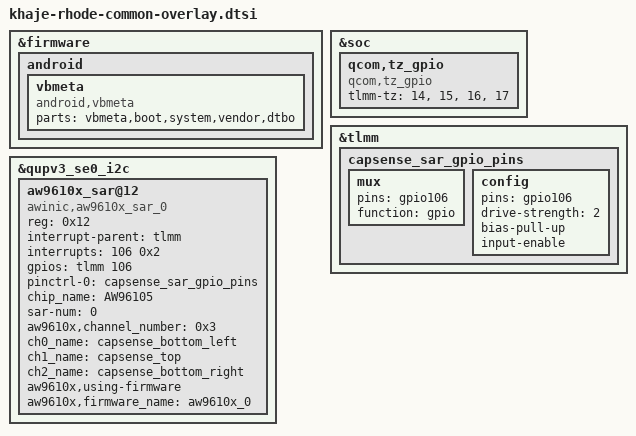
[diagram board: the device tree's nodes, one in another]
/* Copyright (c) 2019, The Linux Foundation. All rights reserved.
 *
 * This program is free software; you can redistribute it and/or modify
 * it under the terms of the GNU General Public License version 2 and
 * only version 2 as published by the Free Software Foundation.
 *
 * This program is distributed in the hope that it will be useful,
 * but WITHOUT ANY WARRANTY; without even the implied warranty of
 * MERCHANTABILITY or FITNESS FOR A PARTICULAR PURPOSE.  See the
 * GNU General Public License for more details.
 */

#include <dt-bindings/interrupt-controller/arm-gic.h>
#include "khaje-moto-common-overlay.dtsi"
#include "khaje-rhode-display.dtsi"
#include "khaje-rhode-fps-overlay_evb.dtsi"
#include "khaje-rhode-touchscreen-overlay.dtsi"

&firmware {
	android {
		vbmeta {
			compatible = "android,vbmeta";
			parts = "vbmeta,boot,system,vendor,dtbo";
		};
	};
};
&soc {
    qcom,tz_gpio {
        compatible = "qcom,tz_gpio";
        tlmm-tz = <14>,
                        <15>,
                        <16>,
                        <17>;
    };
};


&tlmm{
	capsense_sar_gpio_pins: capsense_sar_gpio_pins {
		mux {
			pins = "gpio106";
			function = "gpio";
		};

		config {
			pins = "gpio106";
			drive-strength = <2>;
			bias-pull-up;
			input-enable;
		};
	};
};

&qupv3_se0_i2c {
        status = "ok";
        aw9610x_sar@12 {
            compatible = "awinic,aw9610x_sar_0";
            reg = <0x12>;
            interrupt-parent = <&tlmm>;
            interrupts = <106 0x2>;
            gpios = <&tlmm 106 0x2>;
            pinctrl-names = "default";
            pinctrl-0 = <&capsense_sar_gpio_pins>;
            chip_name = "AW96105";
            sar-num = <0>;
            aw9610x,channel_number = <0x3>;
            ch0_name = "capsense_bottom_left";
            ch1_name = "capsense_top";
            ch2_name = "capsense_bottom_right";
            aw9610x,using-firmware;
            aw9610x,firmware_name = "aw9610x_0";
        };
};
